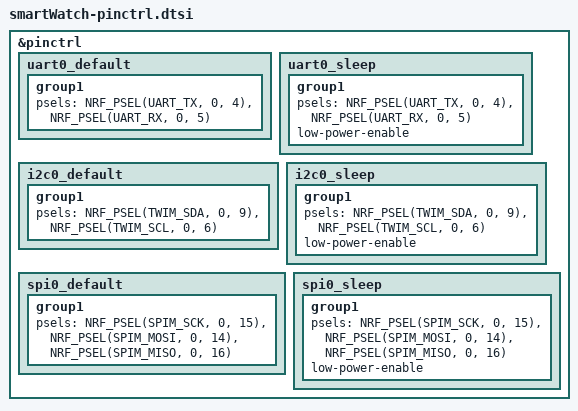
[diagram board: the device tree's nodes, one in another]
/*
 * Copyright (c) 2022 Nordic Semiconductor ASA
 *
 * SPDX-License-Identifier: LicenseRef-Nordic-5-Clause
 */

&pinctrl {
	uart0_default: uart0_default {
		group1 {
			psels = <NRF_PSEL(UART_TX, 0, 4)>,
				<NRF_PSEL(UART_RX, 0, 5)>;
		};
	};

	uart0_sleep: uart0_sleep {
		group1 {
			psels = <NRF_PSEL(UART_TX, 0, 4)>,
				<NRF_PSEL(UART_RX, 0, 5)>;
			low-power-enable;
		};
	};

	i2c0_default: i2c0_default {
		group1 {
			psels = <NRF_PSEL(TWIM_SDA, 0, 9)>,
				<NRF_PSEL(TWIM_SCL, 0, 6)>;
		};
	};

	i2c0_sleep: i2c0_sleep {
		group1 {
			psels = <NRF_PSEL(TWIM_SDA, 0, 9)>,
				<NRF_PSEL(TWIM_SCL, 0, 6)>;
			low-power-enable;
		};
	};

	spi0_default: spi0_default {
		group1 {
			psels = <NRF_PSEL(SPIM_SCK, 0, 15)>,
				<NRF_PSEL(SPIM_MOSI, 0, 14)>,
				<NRF_PSEL(SPIM_MISO, 0, 16)>;
		};
	};

	spi0_sleep: spi0_sleep {
		group1 {
			psels = <NRF_PSEL(SPIM_SCK, 0, 15)>,
				<NRF_PSEL(SPIM_MOSI, 0, 14)>,
				<NRF_PSEL(SPIM_MISO, 0, 16)>;
			low-power-enable;
		};
	};

};
